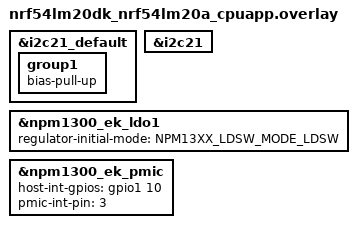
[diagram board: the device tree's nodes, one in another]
/*
 * Copyright (c) 2025 Nordic Semiconductor ASA
 *
 * SPDX-License-Identifier: LicenseRef-Nordic-5-Clause
 */

#include <dt-bindings/regulator/npm13xx.h>

&i2c21_default {
	group1 {
		bias-pull-up;
	};
};

&i2c21 {
	status = "okay";
};

&npm1300_ek_ldo1 {
	regulator-initial-mode = <NPM13XX_LDSW_MODE_LDSW>;
};

&npm1300_ek_pmic {
	host-int-gpios = <&gpio1 10 0>;
	pmic-int-pin = <3>;
};
